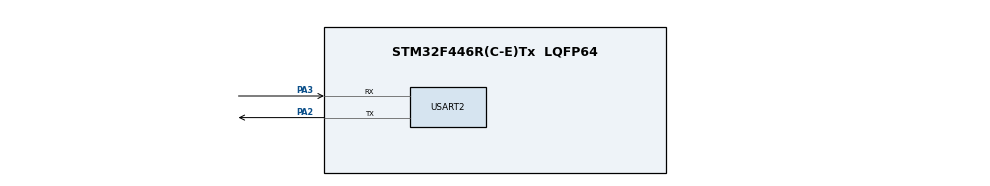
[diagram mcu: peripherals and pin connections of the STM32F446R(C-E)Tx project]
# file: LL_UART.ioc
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Dma.Request0=USART2_TX
Dma.Request1=USART2_RX
Dma.USART2_RX.1.Direction=DMA_PERIPH_TO_MEMORY
Dma.USART2_RX.1.FIFOMode=DMA_FIFOMODE_DISABLE
Dma.USART2_RX.1.Instance=DMA1_Stream5
Dma.USART2_RX.1.MemDataAlignment=DMA_MDATAALIGN_BYTE
Dma.USART2_RX.1.MemInc=DMA_MINC_ENABLE
Dma.USART2_RX.1.Mode=DMA_NORMAL
Dma.USART2_RX.1.PeriphDataAlignment=DMA_PDATAALIGN_BYTE
Dma.USART2_RX.1.PeriphInc=DMA_PINC_DISABLE
Dma.USART2_RX.1.Priority=DMA_PRIORITY_LOW
Dma.USART2_TX.0.Direction=DMA_MEMORY_TO_PERIPH
Dma.USART2_TX.0.FIFOMode=DMA_FIFOMODE_DISABLE
Dma.USART2_TX.0.Instance=DMA1_Stream6
Dma.USART2_TX.0.MemDataAlignment=DMA_MDATAALIGN_BYTE
Dma.USART2_TX.0.MemInc=DMA_MINC_ENABLE
Dma.USART2_TX.0.Mode=DMA_NORMAL
Dma.USART2_TX.0.PeriphDataAlignment=DMA_PDATAALIGN_BYTE
Dma.USART2_TX.0.PeriphInc=DMA_PINC_DISABLE
Dma.USART2_TX.0.Priority=DMA_PRIORITY_LOW
Mcu.Family=STM32F4
Mcu.Name=STM32F446R(C-E)Tx
Mcu.Package=LQFP64
NVIC.DMA1_Stream5_IRQn=true\:0\:0\:false\:false\:false\:false\:true\:true
NVIC.DMA1_Stream6_IRQn=true\:0\:0\:false\:false\:false\:false\:true\:true
NVIC.PriorityGroup=NVIC_PRIORITYGROUP_4
NVIC.USART2_IRQn=true\:0\:0\:false\:false\:false\:true\:true\:true
PA2.Mode=Asynchronous
PA2.Signal=USART2_TX
PA3.Mode=Asynchronous
PA3.Signal=USART2_RX
ProjectManager.HeapSize=0x200
ProjectManager.StackSize=0x400
ProjectManager.TargetToolchain=STM32CubeIDE
RCC.CortexFreq_Value=16000000
RCC.USBFreq_Value=96000000
RCC.VCOOutputFreq_Value=192000000
USART2.VirtualMode=VM_ASYNC
board=custom

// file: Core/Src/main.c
/* USER CODE BEGIN Header */
/**
  ******************************************************************************
  * @file           : main.c
  * @brief          : Main program body
  ******************************************************************************
  * @attention
  *
  * Copyright (c) 2026 STMicroelectronics.
  * All rights reserved.
  *
  * This software is licensed under terms that can be found in the LICENSE file
  * in the root directory of this software component.
  * If no LICENSE file comes with this software, it is provided AS-IS.
  *
  ******************************************************************************
  */
/* USER CODE END Header */
#include "main.h"
#include "dma.h"
#include "usart.h"
#include "gpio.h"

/* USER CODE BEGIN Includes */
#include "stdio.h"
/* USER CODE END Includes */

/* USER CODE BEGIN PV */

#define RXBuffSize 100

char uart_buff_rx[RXBuffSize];
uint16_t rx_index;

uint16_t ReceivedLen;

uint8_t rxDone=0;

char uart_buff[50]={0};
uint8_t counter;

uint16_t buff_len;

uint16_t tx_index;

uint8_t Tx_Done;

uint8_t iDMARX=0;

/* USER CODE END PV */

void SystemClock_Config(void);

/* USER CODE BEGIN 0 */

void UART_Send_Char(char ch)
{
	while (!LL_USART_IsActiveFlag_TXE(USART2));   	// Wait until TX buffer is empty

	LL_USART_TransmitData8(USART2, ch);				// Send byte

	while (!LL_USART_IsActiveFlag_TC(USART2));		// Wait for complete transmission
}

void UART_Send_String(char *ch , uint16_t len)

{
	for (int i=0;i<len;i++)
	{
		while (!LL_USART_IsActiveFlag_TXE(USART2));   	// Wait until TX buffer is empty

		LL_USART_TransmitData8(USART2, ch[i]);				// Send byte

	}

	while (!LL_USART_IsActiveFlag_TC(USART2));		// Wait for complete transmission
}

void USART2_IRQHandler(void)
{
	if (LL_USART_IsActiveFlag_TXE(USART2) && LL_USART_IsEnabledIT_TXE(USART2))
	{
		if (tx_index < buff_len)
		{
			LL_USART_TransmitData8(USART2, uart_buff[tx_index++]);

			if (tx_index == buff_len)
			{
				LL_USART_DisableIT_TXE(USART2);
				LL_USART_EnableIT_TC(USART2);
			}
		}
	}

	if (LL_USART_IsActiveFlag_TC(USART2) && LL_USART_IsEnabledIT_TC(USART2))
	{
	        LL_USART_ClearFlag_TC(USART2);
	        LL_USART_DisableIT_TC(USART2);
	        Tx_Done = 1;
	}

	// RXNE interrupt
	if (LL_USART_IsActiveFlag_RXNE(USART2))
	{
		uart_buff_rx[rx_index++] = LL_USART_ReceiveData8(USART2);
		if(rx_index==RXBuffSize)
		{
			rx_index=0;
		}
	}
	// IDLE line interrupt
	if(LL_USART_IsActiveFlag_IDLE(USART2))
	{
		LL_USART_ClearFlag_IDLE(USART2);
		if(iDMARX==0)
		{
			ReceivedLen=rx_index;
			rx_index=0;
			rxDone=1;
		}

		if(iDMARX==1)
		{
			/* Calculate bytes received */
			ReceivedLen=RXBuffSize-LL_DMA_GetDataLength(DMA1, LL_DMA_STREAM_5);

			/*Clear IDLE flag*/
			LL_USART_ClearFlag_IDLE(USART2);

			/* Stop DMA to preserve received data */
			LL_DMA_DisableStream(DMA1, LL_DMA_STREAM_5);

	        /* Clear any pending DMA flags */
	        LL_DMA_ClearFlag_TC5(DMA1);

	        rxDone = 1;
		}
	}

}

void DMA1_Stream6_IRQHandler(void)
{
    if (LL_DMA_IsActiveFlag_TC6(DMA1))
    {
        LL_DMA_ClearFlag_TC6(DMA1);
        LL_DMA_DisableStream(DMA1, LL_DMA_STREAM_6);

    }
}

void DMA1_Stream5_IRQHandler(void)
{
	if (LL_DMA_IsActiveFlag_TC5(DMA1))
	{
		LL_DMA_ClearFlag_TC5(DMA1);
		LL_DMA_DisableStream(DMA1, LL_DMA_STREAM_5);
		ReceivedLen=RXBuffSize;

	}
}

void UART_Send_IT(void)
{
	tx_index = 0;
	Tx_Done = 0;

	LL_USART_ClearFlag_TC(USART2);
	LL_USART_EnableIT_TXE(USART2);

}

void UART_Send_DMA(uint8_t * ch, uint16_t len)
{
	Tx_Done = 0;

	LL_DMA_DisableStream(DMA1, LL_DMA_STREAM_6);

	LL_DMA_SetPeriphAddress(DMA1, LL_DMA_STREAM_6, LL_USART_DMA_GetRegAddr(USART2));

	LL_DMA_SetMemoryAddress(DMA1, LL_DMA_STREAM_6, (uint32_t)ch);

	LL_DMA_SetDataLength(DMA1, LL_DMA_STREAM_6, len);

    LL_USART_ClearFlag_TC(USART2);

    LL_USART_EnableIT_TC(USART2);

    LL_USART_EnableDMAReq_TX(USART2);

    LL_DMA_EnableIT_TC(DMA1, LL_DMA_STREAM_6);

    LL_DMA_EnableStream(DMA1, LL_DMA_STREAM_6);

}

/* Start UART DMA IDLE reception */
void UART_Receive_DMA_IDLE(uint8_t *ch, uint16_t len)
{
	rxDone = 0;
	ReceivedLen = 0;
	iDMARX=1;

    LL_DMA_DisableStream(DMA1, LL_DMA_STREAM_5);

    LL_DMA_ClearFlag_TC5(DMA1);
    LL_DMA_ClearFlag_HT5(DMA1);
    LL_DMA_ClearFlag_TE5(DMA1);

    LL_DMA_EnableIT_TC(DMA1, LL_DMA_STREAM_5);   // Enable Transfer Complete Interrupt

    LL_USART_ClearFlag_IDLE(USART2);

    LL_USART_EnableIT_IDLE(USART2);

    LL_USART_EnableDMAReq_RX(USART2);  // Enable USART RX via DMA

    LL_DMA_SetMemoryAddress(DMA1, LL_DMA_STREAM_5, (uint32_t)ch);
    LL_DMA_SetPeriphAddress(DMA1, LL_DMA_STREAM_5, LL_USART_DMA_GetRegAddr(USART2));
    LL_DMA_SetDataLength(DMA1, LL_DMA_STREAM_5, len);

    LL_DMA_EnableStream(DMA1, LL_DMA_STREAM_5);
}

/* USER CODE END 0 */

int main(void)
{

  /* MCU Configuration--------------------------------------------------------*/

  /* Reset of all peripherals, Initializes the Flash interface and the Systick. */
  LL_APB2_GRP1_EnableClock(LL_APB2_GRP1_PERIPH_SYSCFG);
  LL_APB1_GRP1_EnableClock(LL_APB1_GRP1_PERIPH_PWR);

  /* System interrupt init*/
  NVIC_SetPriorityGrouping(NVIC_PRIORITYGROUP_4);

  /* SysTick_IRQn interrupt configuration */
  NVIC_SetPriority(SysTick_IRQn, NVIC_EncodePriority(NVIC_GetPriorityGrouping(),15, 0));

  /* Configure the system clock */
  SystemClock_Config();

  /* Initialize all configured peripherals */
  MX_GPIO_Init();
  MX_DMA_Init();
  MX_USART2_UART_Init();

  /* Infinite loop */
  while (1)
  {

    /* USER CODE BEGIN 3 */
	 if(rxDone==0)
	 {
		UART_Receive_DMA_IDLE((uint8_t*)uart_buff_rx,RXBuffSize);

		while(rxDone==0);
		rxDone=0;
		UART_Send_String(uart_buff_rx,ReceivedLen);

	 }

  }
  /* USER CODE END 3 */
}

void SystemClock_Config(void)
{
  LL_FLASH_SetLatency(LL_FLASH_LATENCY_0);
  while(LL_FLASH_GetLatency()!= LL_FLASH_LATENCY_0)
  {
  }
  LL_PWR_SetRegulVoltageScaling(LL_PWR_REGU_VOLTAGE_SCALE3);
  LL_PWR_DisableOverDriveMode();
  LL_RCC_HSI_SetCalibTrimming(16);
  LL_RCC_HSI_Enable();

   /* Wait till HSI is ready */
  while(LL_RCC_HSI_IsReady() != 1)
  {

  }
  LL_RCC_SetAHBPrescaler(LL_RCC_SYSCLK_DIV_1);
  LL_RCC_SetAPB1Prescaler(LL_RCC_APB1_DIV_1);
  LL_RCC_SetAPB2Prescaler(LL_RCC_APB2_DIV_1);
  LL_RCC_SetSysClkSource(LL_RCC_SYS_CLKSOURCE_HSI);

   /* Wait till System clock is ready */
  while(LL_RCC_GetSysClkSource() != LL_RCC_SYS_CLKSOURCE_STATUS_HSI)
  {

  }
  LL_Init1msTick(16000000);
  LL_SetSystemCoreClock(16000000);
  LL_RCC_SetTIMPrescaler(LL_RCC_TIM_PRESCALER_TWICE);
}

void Error_Handler(void)
{
  __disable_irq();
  while (1)
  {
  }
}
